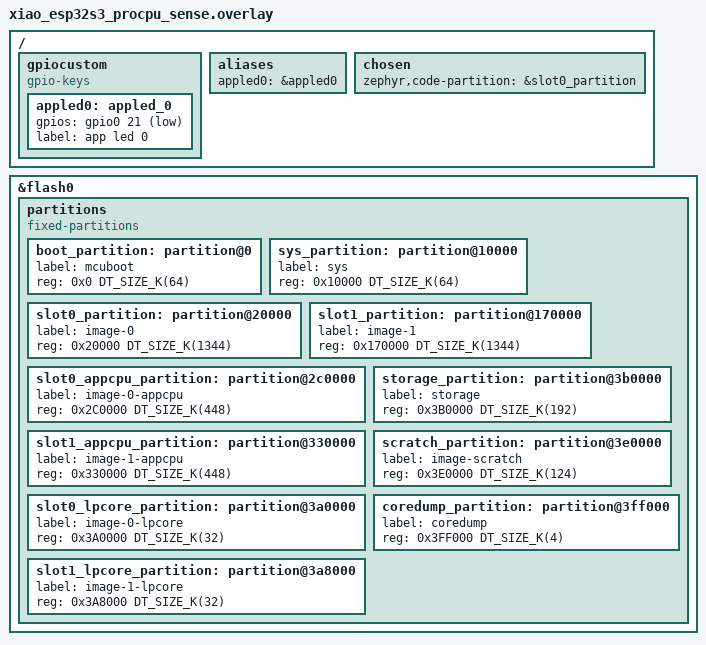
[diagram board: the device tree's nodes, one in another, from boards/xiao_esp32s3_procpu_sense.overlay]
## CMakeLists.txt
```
cmake_minimum_required(VERSION 3.20.0)

find_package(Zephyr REQUIRED HINTS $ENV{ZEPHYR_BASE})
project(dfu_01)

target_sources(app PRIVATE src/main.c)
```

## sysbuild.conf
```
SB_CONFIG_BOOTLOADER_MCUBOOT=y
#SB_CONFIG_MCUBOOT_USE_ALL_AVAILABLE_RAM=y
SB_CONFIG_MCUBOOT_MODE_OVERWRITE_ONLY=y
SB_CONFIG_BOOT_SIGNATURE_TYPE_ED25519=y
#SB_CONFIG_BOOT_SIGNATURE_KEY_FILE="../uhkeys/root-ed25519.pem"
SB_CONFIG_BOOT_SIGNATURE_KEY_FILE="/Users/yogesh/projects/temp/xiao/learn_xiao/firmware/keys/root-ed25519.pem"
```

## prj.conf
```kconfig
CONFIG_REBOOT=y

CONFIG_MCUMGR_TRANSPORT_NETBUF_SIZE=1024


CONFIG_BT=y
CONFIG_BT_PERIPHERAL=y
CONFIG_BT_DEVICE_NAME="ZephyrDFU"

# MCUmgr over BLE transport
CONFIG_MCUMGR_TRANSPORT_BT=y

# Helps MCUmgr SMP GATT service registration on many boards
CONFIG_BT_GATT_DYNAMIC_DB=y

# (Optional) better throughput if your controller supports it
CONFIG_BT_L2CAP_TX_MTU=247
CONFIG_BT_BUF_ACL_RX_SIZE=251
CONFIG_BT_BUF_ACL_TX_SIZE=251

CONFIG_PRINTK=y

CONFIG_BT_DIS=y

CONFIG_BT_DIS_PNP=n
CONFIG_BT_DIS_FW_REV=y
CONFIG_BT_DIS_HW_REV=y
CONFIG_BT_DIS_SERIAL_NUMBER=y
CONFIG_BT_DIS_SETTINGS=y
CONFIG_BT_DIS_STR_MAX=31

CONFIG_BT_PERIPHERAL=y
#CONFIG_NCS_SAMPLE_MCUMGR_BT_OTA_DFU=y
#CONFIG_MCUMGR_TRANSPORT_BT_PERM_RW_AUTHEN=y
# Core MCUmgr + SMP over BLE
CONFIG_MCUMGR=y
CONFIG_NET_BUF=y
CONFIG_ZCBOR=y
CONFIG_CRC=y
CONFIG_MCUMGR_TRANSPORT_BT=y
CONFIG_MCUMGR_TRANSPORT_BT_CONN_PARAM_CONTROL=y

# Image management + flash streaming
CONFIG_IMG_MANAGER=y
CONFIG_STREAM_FLASH=y
CONFIG_FLASH_MAP=y
CONFIG_FLASH=y

# SMP groups
CONFIG_MCUMGR_GRP_IMG=y
CONFIG_MCUMGR_GRP_OS=y
CONFIG_MCUMGR_GRP_OS_BOOTLOADER_INFO=y

# Reassembly + speed‑up (large MTU / buffers)
CONFIG_MCUMGR_TRANSPORT_BT_REASSEMBLY=y


CONFIG_BT_DIS_SERIAL_NUMBER_STR="SERIAL_NUMBER_123456"
CONFIG_BT_DIS_MANUF="test_manufacturer"
CONFIG_BT_DIS_HW_REV_STR="R1.01.01.01"
CONFIG_BT_DIS_MODEL="R1.01.01.01"

CONFIG_BT_DIS_FW_REV_STR="00.00.13.00"
CONFIG_MCUBOOT_IMGTOOL_SIGN_VERSION="0.0.13+0"
```

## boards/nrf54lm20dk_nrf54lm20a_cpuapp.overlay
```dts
/delete-node/ &boot_partition;
/delete-node/ &slot0_partition;
/delete-node/ &slot1_partition;
/delete-node/ &storage_partition;

/ {
    gpiocustom {
        compatible = "gpio-keys";
        appled0: appled_0 {
            gpios = <&gpio1 22 GPIO_ACTIVE_HIGH>;
            label = "app led 0";
        };
    };

    aliases {
        appled0 = &appled0;
    };

    chosen {
		zephyr,flash-controller = &rram_controller;
		zephyr,flash = &cpuapp_rram;
		zephyr,code-partition = &slot0_partition;
	};
};


&cpuapp_rram {
	partitions {
		compatible = "fixed-partitions";
		#address-cells = <1>;
		#size-cells = <1>;

		/* nRF54LM20A has 2036 kB of non-volatile memory (RRAM) but the last
		 * 96 kB are reserved for the FLPR MCU, so we have ~1940 kB available.
		 */

		boot_partition: partition@0 {
			label = "mcuboot";
			reg = <0x0 DT_SIZE_K(96)>;
		};

		slot0_partition: partition@18000 {
			label = "image-0";
			reg = <0x18000 DT_SIZE_K(900)>;
		};

		slot1_partition: partition@f9000 {
			label = "image-1";
			reg = <0xf9000 DT_SIZE_K(900)>;
		};
		
		cfg_partition: partition@1da000 {
			label = "cfg";
			reg = <0x1da000 DT_SIZE_K(12)>;
		};

		storage_partition: partition@1dd000 {
			label = "storage";
			reg = <0x1dd000 DT_SIZE_K(32)>;
		};
	};
};
```

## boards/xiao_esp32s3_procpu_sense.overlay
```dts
/delete-node/ &boot_partition;
/delete-node/ &sys_partition;
/delete-node/ &slot0_partition;
/delete-node/ &slot1_partition;

/ {
    gpiocustom {
        compatible = "gpio-keys";
        appled0: appled_0 {
            gpios = <&gpio0 21 GPIO_ACTIVE_LOW>;
            label = "app led 0";
        };
    };

    aliases {
        appled0 = &appled0;
    };

	chosen {
		zephyr,code-partition = &slot0_partition;
	};
};

&flash0 {
	partitions {
		compatible = "fixed-partitions";
		#address-cells = <1>;
		#size-cells = <1>;

		boot_partition: partition@0 {
			label = "mcuboot";
			reg = <0x0 DT_SIZE_K(64)>;
		};

		sys_partition: partition@10000 {
			label = "sys";
			reg = <0x10000 DT_SIZE_K(64)>;
		};

		slot0_partition: partition@20000 {
			label = "image-0";
			reg = <0x20000 DT_SIZE_K(1344)>;
		};

		slot1_partition: partition@170000 {
			label = "image-1";
			reg = <0x170000 DT_SIZE_K(1344)>;
		};

		slot0_appcpu_partition: partition@2c0000 {
			label = "image-0-appcpu";
			reg = <0x2C0000 DT_SIZE_K(448)>;
		};

		slot1_appcpu_partition: partition@330000 {
			label = "image-1-appcpu";
			reg = <0x330000 DT_SIZE_K(448)>;
		};

		slot0_lpcore_partition: partition@3a0000 {
			label = "image-0-lpcore";
			reg = <0x3A0000 DT_SIZE_K(32)>;
		};

		slot1_lpcore_partition: partition@3a8000 {
			label = "image-1-lpcore";
			reg = <0x3A8000 DT_SIZE_K(32)>;
		};

		storage_partition: partition@3b0000 {
			label = "storage";
			reg = <0x3B0000 DT_SIZE_K(192)>;
		};

		scratch_partition: partition@3e0000 {
			label = "image-scratch";
			reg = <0x3E0000 DT_SIZE_K(124)>;
		};

		coredump_partition: partition@3ff000 {
			label = "coredump";
			reg = <0x3FF000 DT_SIZE_K(4)>;
		};
	};
};
```

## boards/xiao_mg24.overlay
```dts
/delete-node/ &boot_partition;
/delete-node/ &slot0_partition;
/delete-node/ &slot1_partition;
/delete-node/ &storage_partition;

/ {
    gpiocustom {
        compatible = "gpio-keys";
        appled0: appled_0 {
            gpios = <&gpioa 7 GPIO_ACTIVE_LOW>;
            label = "app led 0";
        };
    };

    aliases {
        appled0 = &appled0;
    };

    chosen {
		zephyr,bt-hci = &bt_hci_silabs;
		zephyr,code-partition = &slot0_partition;
		zephyr,console = &usart0;
		zephyr,flash = &flash0;
		zephyr,shell-uart = &usart0;
		zephyr,sram = &sram0;
		zephyr,uart-pipe = &usart0;
	};
};

&flash0 {
	partitions {
		compatible = "fixed-partitions";
		#address-cells = <1>;
		#size-cells = <1>;

		/* Reserve 96 kB for the bootloader */
		boot_partition: partition@0 {
			reg = <0x0 DT_SIZE_K(96)>;
			label = "mcuboot";
		};

		/* Reserve 696 kB for the application in slot 0 */
		slot0_partition: partition@18000 {
			reg = <0x00018000 0x000AE000>;
			label = "image-0";
		};

		/* Reserve 696 kB for the application in slot 1 */
		slot1_partition: partition@C6000 {
			reg = <0x000C6000 0x000AE000>;
			label = "image-1";
		};

		config_partition: partition@174000 {
			reg = <0x00174000 DT_SIZE_K(16)>;
			label = "config";
		};

		/* Set 32 kB of storage at the end of the 1536 kB of flash */
		storage_partition: partition@178000 {
			reg = <0x00178000 DT_SIZE_K(32)>;
			label = "storage";
		};
	};
};
```

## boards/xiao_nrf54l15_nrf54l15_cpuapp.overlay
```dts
/delete-node/ &boot_partition;
/delete-node/ &slot0_partition;
/delete-node/ &slot1_partition;
/delete-node/ &storage_partition;

/ {
    gpiocustom {
        compatible = "gpio-keys";
        appled0: appled_0 {
            gpios = <&gpio2 0 GPIO_ACTIVE_LOW>;
            label = "app led 0";
        };
    };

    aliases {
        appled0 = &appled0;
    };

    chosen {
		zephyr,flash-controller = &rram_controller;
		zephyr,flash = &cpuapp_rram;
		zephyr,code-partition = &slot0_partition;
	};
};

&cpuapp_rram {
    partitions {
        compatible = "fixed-partitions";
        #address-cells = <1>;
        #size-cells = <1>;

        boot_partition: partition@0 {
            label = "mcuboot";
            reg = <0x0 DT_SIZE_K(96)>;
        };

        slot0_partition: partition@18000 {
            label = "image-0";
            reg = <0x18000 DT_SIZE_K(600)>;
        };

        slot1_partition: partition@ae000 {
            label = "image-1";
            reg = <0xAE000 DT_SIZE_K(600)>;
        };

        storage_partition: partition@144000 {
            label = "storage";
            reg = <0x144000 DT_SIZE_K(36)>;
        };
    };
};
```

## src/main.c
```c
#include <zephyr/kernel.h>
#include <zephyr/bluetooth/bluetooth.h>
#include <zephyr/bluetooth/gap.h>
#include <zephyr/bluetooth/uuid.h>

#define DEVICE_NAME CONFIG_BOARD
#define DEVICE_NAME_LEN (sizeof(DEVICE_NAME) - 1)

/* Step 1: Prepare the advertising data */
static const struct bt_data ad[] = {
    BT_DATA_BYTES(BT_DATA_FLAGS, BT_LE_AD_NO_BREDR),
    BT_DATA(BT_DATA_NAME_COMPLETE, DEVICE_NAME, DEVICE_NAME_LEN),
};

/* Step 2: Prepare the scan response data */
static const uint8_t sd_uuid[] = {
	BT_UUID_128_ENCODE(0x00001523, 0x1212, 0xefde, 0x1523, 0x785feabcd123)
};

static const struct bt_data sd[] = {
	BT_DATA(BT_DATA_UUID128_ALL, sd_uuid, sizeof(sd_uuid)),
};

#define ADV_INTERVAL_1S 1600	/* 1 second in units of 0.625 ms */

static const struct bt_le_adv_param *adv_param =
	BT_LE_ADV_PARAM(BT_LE_ADV_OPT_CONN | BT_LE_ADV_OPT_USE_IDENTITY,
			ADV_INTERVAL_1S,
			ADV_INTERVAL_1S,
			NULL);

int main(void)
{
    int err;

	printk("Starting Bluetooth DFU Sample\n");
	printk("Device Name: %s\n", DEVICE_NAME);

	k_sleep(K_SECONDS(5));

    /* Step 3: Initialize the Bluetooth Subsystem */
    err = bt_enable(NULL);
    if (err) {
		printk("Bluetooth initialization failed (err %d)\n", err);
        return 0;
    }

    /* Step 4: Start advertising */
    /* BT_LE_ADV_NCONN: non-connectable advertising */
	err = bt_le_adv_start(adv_param, ad, ARRAY_SIZE(ad), sd, ARRAY_SIZE(sd));
    if (err) {
		printk("Advertising failed to start (err %d)\n", err);
        return 0;
    }

	while(1)
	{
		printk("Advertising...\n");
		printk("FW: %s\n", CONFIG_BT_DIS_FW_REV_STR);
		k_sleep(K_SECONDS(5));
	}
    return 0;
}
```
